# ATmega162 device description
Architecture: AVR8; Family: megaAVR
Registers are 8-bit, access not given, no defined reset value unless marked. A register's access mark holds for its fields unless they carry their own. Offsets are from the block's base; [hi:lo] are bit positions.

## LOCKBIT — Lockbits
Instances: LOCKBIT 0 in lockbits
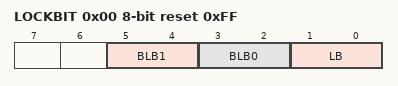
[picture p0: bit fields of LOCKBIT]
0x00 LOCKBIT reset 0xFF
  [5:4] BLB1 — Boot Loader Protection Mode
    0=LPM_SPM_DISABLE (LPM and SPM prohibited in Boot Section); 1=LPM_DISABLE (LPM prohibited in Boot Section); 2=SPM_DISABLE (SPM prohibited in Boot Section); 3=NO_LOCK (No lock on SPM and LPM in Boot Section)
  [3:2] BLB0 — Boot Loader Protection Mode
    0=LPM_SPM_DISABLE (LPM and SPM prohibited in Application Section); 1=LPM_DISABLE (LPM prohibited in Application Section); 2=SPM_DISABLE (SPM prohibited in Application Section); 3=NO_LOCK (No lock on SPM and LPM in Application Section)
  [1:0] LB — Memory Lock
    0=PROG_VER_DISABLED (Further programming and verification disabled); 2=PROG_DISABLED (Further programming disabled); 3=NO_LOCK (No memory lock features enabled)

## TC1 (TC16 module) — Timer/Counter, 16-bit
Instances: TC1 0x00
0x44 ICR1 16-bit — Timer/Counter1 Input Capture Register Bytes
0x48 OCR1B 16-bit — Timer/Counter1 Output Compare Register B Bytes
0x4A OCR1A 16-bit — Timer/Counter1 Output Compare Register A Bytes
0x4C TCNT1 16-bit — Timer/Counter1 Bytes
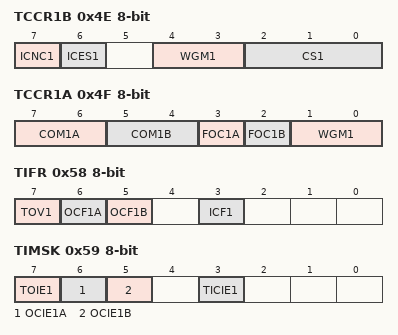
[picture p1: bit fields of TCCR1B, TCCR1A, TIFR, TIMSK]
0x4E TCCR1B — Timer/Counter1 Control Register B
  [7] ICNC1 — Input Capture 1 Noise Canceler
  [6] ICES1 — Input Capture 1 Edge Select
  [4:3] WGM1 (bit 2 of the value upward) — Pulse Width Modulator Select Bits
  [2:0] CS1 — Clock Select1 bits
    0=NO_CLOCK_SOURCE_STOPPED; 1=RUNNING_NO_PRESCALING; 2=RUNNING_CLK_8; 3=RUNNING_CLK_64; 4=RUNNING_CLK_256; 5=RUNNING_CLK_1024; 6=RUNNING_EXTCLK_TN_FALLING_EDGE; 7=RUNNING_EXTCLK_TN_RISING_EDGE
0x4F TCCR1A — Timer/Counter1 Control Register A
  [7:6] COM1A — Compare Output Mode 1A, bits
  [5:4] COM1B — Compare Output Mode 1B, bits
  [3] FOC1A — Force Output Compare for Channel A
  [2] FOC1B — Force Output Compare for Channel B
  [1:0] WGM1 — Pulse Width Modulator Select Bits
0x58 TIFR — Timer/Counter Interrupt Flag register
  [7] TOV1 — Timer/Counter1 Overflow Flag
  [6] OCF1A — Output Compare Flag 1A
  [5] OCF1B — Output Compare Flag 1B
  [3] ICF1 — Input Capture Flag 1
0x59 TIMSK — Timer/Counter Interrupt Mask Register
  [7] TOIE1 — Timer/Counter1 Overflow Interrupt Enable
  [6] OCIE1A — Timer/Counter1 Output CompareA Match Interrupt Enable
  [5] OCIE1B — Timer/Counter1 Output CompareB Match Interrupt Enable
  [3] TICIE1 — Timer/Counter1 Input Capture Interrupt Enable

## TC3 (TC16 module) — Timer/Counter, 16-bit
Instances: TC3 0x00
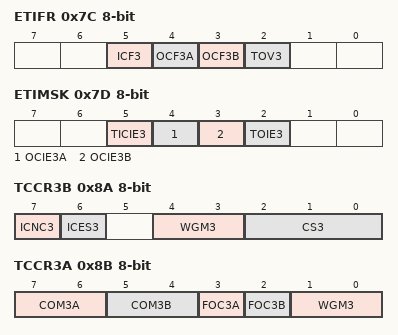
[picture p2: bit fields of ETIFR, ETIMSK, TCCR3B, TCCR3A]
0x7C ETIFR — Extended Timer/Counter Interrupt Flag register
  [5] ICF3 — Input Capture Flag 3
  [4] OCF3A — Output Compare Flag 3A
  [3] OCF3B — Output Compare Flag 3B
  [2] TOV3 — Timer/Counter3 Overflow Flag
0x7D ETIMSK — Extended Timer/Counter Interrupt Mask Register
  [5] TICIE3 — Timer/Counter3 Input Capture Interrupt Enable
  [4] OCIE3A — Timer/Counter3 Output CompareA Match Interrupt Enable
  [3] OCIE3B — Timer/Counter3 Output CompareB Match Interrupt Enable
  [2] TOIE3 — Timer/Counter3 Overflow Interrupt Enable
0x80 ICR3 16-bit — Timer/Counter3 Input Capture Register Bytes
0x84 OCR3B 16-bit — Timer/Counter3 Output Compare Register B Bytes
0x86 OCR3A 16-bit — Timer/Counter3 Output Compare Register A Bytes
0x88 TCNT3 16-bit — Timer/Counter3 Bytes
0x8A TCCR3B — Timer/Counter3 Control Register B
  [7] ICNC3 — Input Capture 3 Noise Canceler
  [6] ICES3 — Input Capture 3 Edge Select
  [4:3] WGM3 (bit 2 of the value upward) — Pulse Width Modulator Select Bits
  [2:0] CS3 — Clock Select3 bits
    0=NO_CLOCK_SOURCE_STOPPED; 1=RUNNING_NO_PRESCALING; 2=RUNNING_CLK_8; 3=RUNNING_CLK_64; 4=RUNNING_CLK_256; 5=RUNNING_CLK_1024; 6=RUNNING_CLK_16; 7=RUNNING_CLK_32
0x8B TCCR3A — Timer/Counter3 Control Register A
  [7:6] COM3A — Compare Output Mode 3A, bits
  [5:4] COM3B — Compare Output Mode 3B, bits
  [3] FOC3A — Force Output Compare for Channel A
  [2] FOC3B — Force Output Compare for Channel B
  [1:0] WGM3 — Pulse Width Modulator Select Bits
